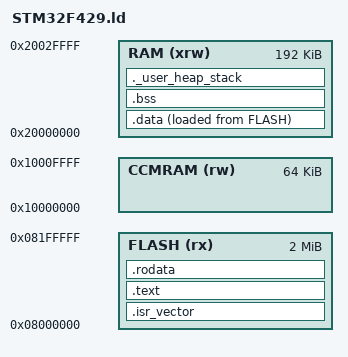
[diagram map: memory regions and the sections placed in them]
ENTRY(Reset_Handler)
_estack = 0x2002FFFF;
_Min_Heap_Size = 0x200;
_Min_Stack_Size = 0x400;

MEMORY
{
    FLASH (rx)       : ORIGIN = 0x8000000,  LENGTH = 2048K
    RAM (xrw)        : ORIGIN = 0x20000000, LENGTH = 192K
    CCMRAM (rw)      : ORIGIN = 0x10000000, LENGTH = 64K
}

SECTIONS
{
  .isr_vector :
  {
    . = ALIGN(4);
    KEEP(*(.isr_vector)) /* Startup code */
    . = ALIGN(4);
  } >FLASH

  .text :
  {
    . = ALIGN(4);
    *(.text)           /* .text sections (code) */
    *(.text*)          /* .text* sections (code) */
    *(.glue_7)         /* glue arm to thumb code */
    *(.glue_7t)        /* glue thumb to arm code */
    *(.eh_frame)

    KEEP (*(.init))
    KEEP (*(.fini))

    . = ALIGN(4);
    _etext = .;
  } >FLASH

  .rodata :
  {
    . = ALIGN(4);
    *(.rodata)
    *(.rodata*)
    . = ALIGN(4);
  } >FLASH

  _sidata = LOADADDR(.data);

  .data : 
  {
    . = ALIGN(4);
    _sdata = .;
    *(.data)
    *(.data*)

    . = ALIGN(4);
    _edata = .;
  } >RAM AT> FLASH

  . = ALIGN(4);
  .bss :
  {
    _sbss = .;
    __bss_start__ = _sbss;
    *(.bss)
    *(.bss*)
    *(COMMON)

    . = ALIGN(4);
    _ebss = .;
    __bss_end__ = _ebss;
  } >RAM

  ._user_heap_stack :
  {
    . = ALIGN(4);
    PROVIDE ( end = . );
    PROVIDE ( _end = . );
    . = . + _Min_Heap_Size;
    . = . + _Min_Stack_Size;
    . = ALIGN(4);
  } >RAM
}
